# UART2 register map
Registers from a debugger description file.
Registers are 32-bit, access not given, no defined reset value unless marked. A register's access mark holds for its fields unless they carry their own. Addresses are absolute; registers are grouped by the start of their names; lines under a group give offsets from that group; [hi:lo] are bit positions; {n}, {i} and the like mark numbered series; 'fields as' and 'values as' point back to an identical list; <NAME> marks a mode.

## UART2
0x40061000 UART2/THR
  [7:0] THR
0x40061000 UART2/DLL
  [7:0] DLL
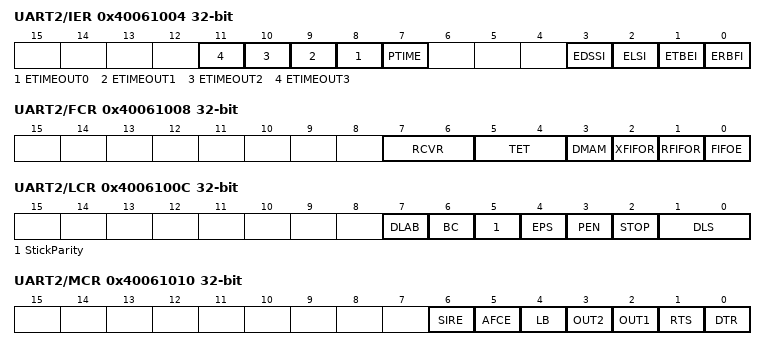
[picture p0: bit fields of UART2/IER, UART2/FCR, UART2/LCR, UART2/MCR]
0x40061004 UART2/IER
  [n+8] ETIMEOUT{n} (n=0..3), [7] PTIME, [3] EDSSI, [2] ELSI, [1] ETBEI, [0] ERBFI
0x40061004 UART2/DLH
  [7:0] DLH
0x40061008 UART2/FCR
  [7:6] RCVR, [5:4] TET, [3] DMAM, [2] XFIFOR, [1] RFIFOR, [0] FIFOE
0x4006100C UART2/LCR
  [7] DLAB, [6] BC, [5] StickParity, [4] EPS, [3] PEN, [2] STOP, [1:0] DLS
0x40061010 UART2/MCR
  [6] SIRE, [5] AFCE, [4] LB, [3] OUT2, [2] OUT1, [1] RTS, [0] DTR
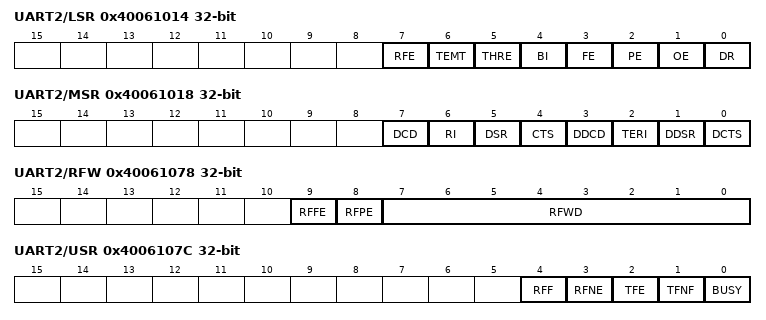
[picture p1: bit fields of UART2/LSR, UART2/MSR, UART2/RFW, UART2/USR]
0x40061014 UART2/LSR ro
  [7] RFE, [6] TEMT, [5] THRE, [4] BI, [3] FE, [2] PE, [1] OE, [0] DR
0x40061018 UART2/MSR ro
  [7] DCD, [6] RI, [5] DSR, [4] CTS, [3] DDCD, [2] TERI, [1] DDSR, [0] DCTS
0x4006101C UART2/SCR
  [7:0] SCR
0x40061030 UART2/STHR
  [7:0] STHR
0x40061070 UART2/FAR
  [0] FAR
0x40061074 UART2/TFR ro
  [7:0] TFR
0x40061078 UART2/RFW
  [9] RFFE, [8] RFPE, [7:0] RFWD
0x4006107C UART2/USR ro
  [4] RFF, [3] RFNE, [2] TFE, [1] TFNF, [0] BUSY
0x40061080 UART2/TFL ro
  [4:0] TFL
0x40061084 UART2/RFL ro
  [4:0] RFL
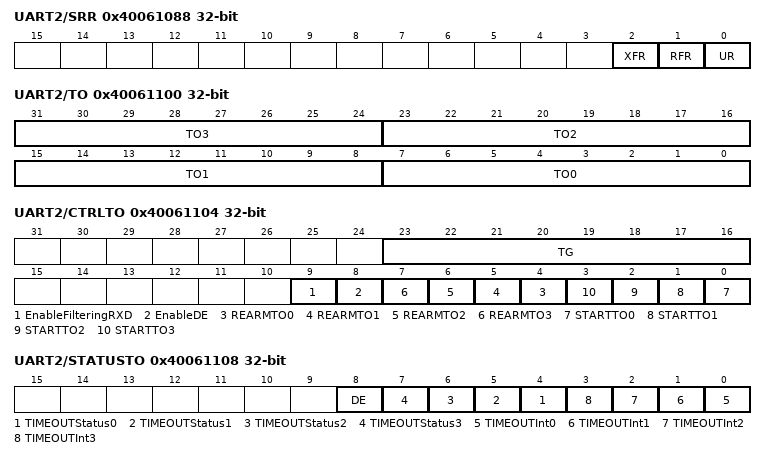
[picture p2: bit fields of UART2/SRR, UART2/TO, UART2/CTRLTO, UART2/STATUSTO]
0x40061088 UART2/SRR
  [2] XFR, [1] RFR, [0] UR
0x4006108C UART2/SRTS
  [0] SRTS
0x40061090 UART2/SBCR
  [0] SBCR
0x40061098 UART2/SFE
  [0] SFE
0x4006109C UART2/SRT
  [1:0] SRCVR
0x400610A0 UART2/STET
  [1:0] STET
0x400610A4 UART2/HTX
  [0] HTX
0x400610F8 UART2/UCV ro
  [31:0] Version
0x400610FC UART2/CTR ro
  [31:0] ID
0x40061100 UART2/TO
  [8n+7:8n] TO{n} (n=0..3)
0x40061104 UART2/CTRLTO
  [23:16] TG, [9] EnableFilteringRXD, [8] EnableDE, [n+4] REARMTO{n} (n=0..3), [n] STARTTO{n} (n=0..3)
0x40061108 UART2/STATUSTO
  [8] DE, [n+4] TIMEOUTStatus{n} (n=0..3), [n] TIMEOUTInt{n} (n=0..3)
